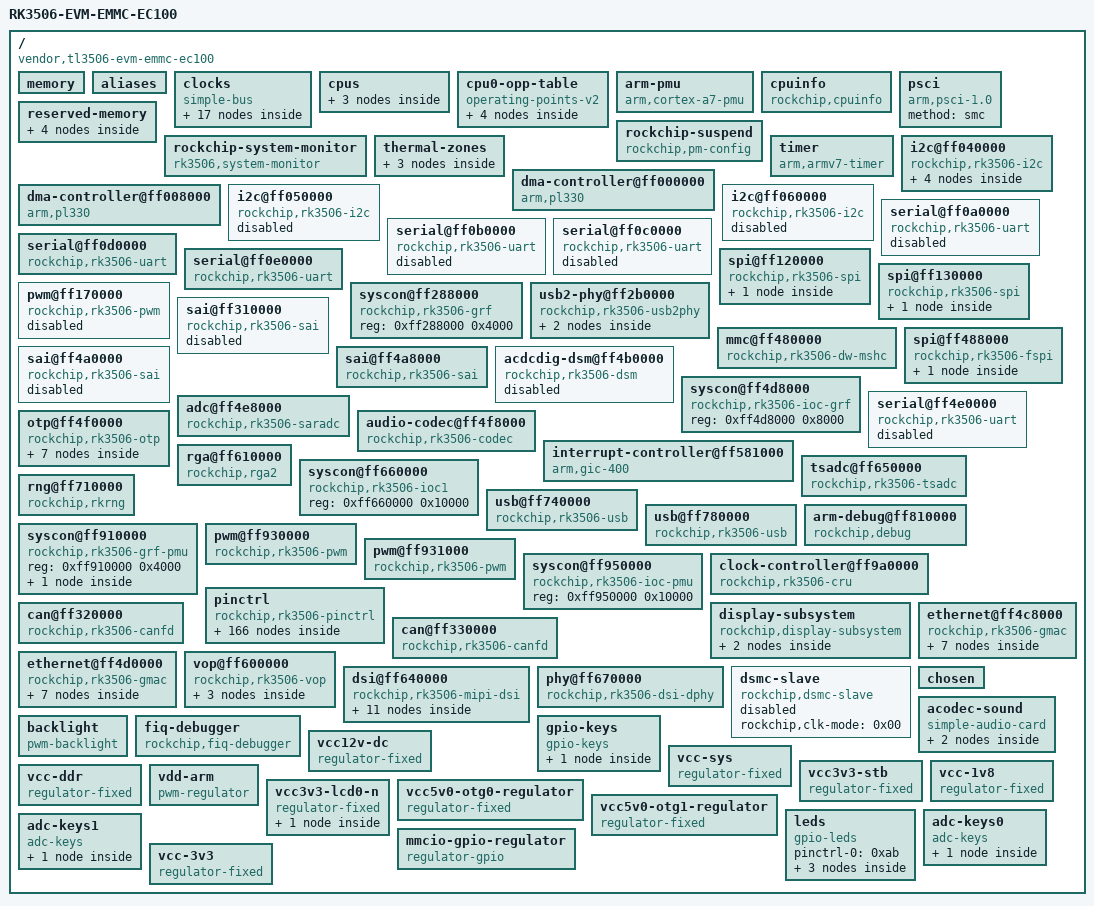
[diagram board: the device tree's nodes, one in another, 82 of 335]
/dts-v1/;

/memreserve/	0x0000000000063000 0x000000000000b000;
/ {
	serial-number = "e6a45d5007608a23";
	#address-cells = <0x01>;
	#size-cells = <0x01>;
	compatible = "vendor,tl3506-evm-emmc-ec100\0rockchip,rk3506";
	interrupt-parent = <0x01>;
	model = "RK3506-EVM-EMMC-EC100";

	memory {
		reg = <0x00 0x20000000 0x00 0x00 0x00 0x00 0x00 0x00 0x00 0x00 0x00 0x00 0x00 0x00 0x00 0x00 0x00 0x00 0x00 0x00 0x00 0x00 0x00 0x00>;
		device_type = "memory";
	};

	aliases {
		gpio0 = "/pinctrl/gpio@ff940000";
		gpio1 = "/pinctrl/gpio@ff870000";
		gpio2 = "/pinctrl/gpio@ff1c0000";
		gpio3 = "/pinctrl/gpio@ff1d0000";
		gpio4 = "/pinctrl/gpio@ff1e0000";
		i2c0 = "/i2c@ff040000";
		i2c1 = "/i2c@ff050000";
		i2c2 = "/i2c@ff060000";
		serial0 = "/serial@ff0a0000";
		serial1 = "/serial@ff0b0000";
		serial2 = "/serial@ff0c0000";
		serial3 = "/serial@ff0d0000";
		serial4 = "/serial@ff0e0000";
		serial5 = "/serial@ff4e0000";
		spi0 = "/spi@ff120000";
		spi1 = "/spi@ff130000";
		spi2 = "/spi@ff488000";
		spi3 = "/flexbus@ff880000/fspi";
		spi4 = "/flexbus@ff880000/spi";
		ethernet0 = "/ethernet@ff4c8000";
		ethernet1 = "/ethernet@ff4d0000";
		gpio5 = "/i2c@ff040000/gpio@20";
	};

	clocks {
		compatible = "simple-bus";
		#address-cells = <0x01>;
		#size-cells = <0x01>;
		ranges;

		clk-rc {
			compatible = "fixed-clock";
			#clock-cells = <0x00>;
			clock-frequency = <0x61a80>;
			clock-output-names = "clk_rc";
		};

		xin24m {
			compatible = "fixed-clock";
			#clock-cells = <0x00>;
			clock-frequency = <0x16e3600>;
			clock-output-names = "xin24m";
		};

		xin32k {
			compatible = "fixed-clock";
			#clock-cells = <0x00>;
			clock-frequency = <0x8000>;
			clock-output-names = "xin32k";
		};

		clk-spdifrx-to-asrc {
			compatible = "fixed-clock";
			#clock-cells = <0x00>;
			clock-frequency = <0x00>;
			clock-output-names = "clk_spdifrx_to_asrc";
		};

		mclkin-sai0 {
			compatible = "fixed-clock";
			#clock-cells = <0x00>;
			clock-frequency = <0x00>;
			clock-output-names = "sai0_mclk_in";
		};

		mclkin-sai1 {
			compatible = "fixed-clock";
			#clock-cells = <0x00>;
			clock-frequency = <0x00>;
			clock-output-names = "sai1_mclk_in";
		};

		mclkin-sai2 {
			compatible = "fixed-clock";
			#clock-cells = <0x00>;
			clock-frequency = <0x00>;
			clock-output-names = "sai2_mclk_in";
		};

		mclkin-sai3 {
			compatible = "fixed-clock";
			#clock-cells = <0x00>;
			clock-frequency = <0x00>;
			clock-output-names = "sai3_mclk_in";
		};

		mclkout-sai0@ff910004 {
			compatible = "rockchip,clk-out";
			reg = <0xff910004 0x04>;
			clocks = <0x02 0x9e>;
			#clock-cells = <0x00>;
			clock-output-names = "mclk_sai0_to_io";
			rockchip,bit-shift = <0x08>;
		};

		mclkout-sai1@ff910004 {
			compatible = "rockchip,clk-out";
			reg = <0xff910004 0x04>;
			clocks = <0x02 0xa1>;
			#clock-cells = <0x00>;
			clock-output-names = "mclk_sai1_to_io";
			rockchip,bit-shift = <0x09>;
			phandle = <0x10>;
		};

		mclkout-sai2@ff288004 {
			compatible = "rockchip,clk-out";
			reg = <0xff288004 0x04>;
			clocks = <0x02 0xc1>;
			#clock-cells = <0x00>;
			clock-output-names = "mclk_sai2_to_io";
			rockchip,bit-shift = <0x02>;
		};

		mclkout-sai3@ff288004 {
			compatible = "rockchip,clk-out";
			reg = <0xff288004 0x04>;
			clocks = <0x02 0xc5>;
			#clock-cells = <0x00>;
			clock-output-names = "mclk_sai3_to_io";
			rockchip,bit-shift = <0x03>;
		};

		pvtpll-core@ff840000 {
			compatible = "rockchip,rk3506-core-pvtpll\0syscon";
			reg = <0xff840000 0x100>;
			#clock-cells = <0x00>;
			clock-output-names = "clk_core_pvtpll";
			assigned-clocks = <0x03>;
			assigned-clock-rates = <0x47868c00>;
			phandle = <0x03>;
		};

		sai0-fs {
			compatible = "fixed-clock";
			#clock-cells = <0x00>;
			clock-frequency = <0x00>;
			clock-output-names = "sai0_fs";
		};

		sai1-fs {
			compatible = "fixed-clock";
			#clock-cells = <0x00>;
			clock-frequency = <0x00>;
			clock-output-names = "sai1_fs";
		};

		sai2-fs {
			compatible = "fixed-clock";
			#clock-cells = <0x00>;
			clock-frequency = <0x00>;
			clock-output-names = "sai2_fs";
		};

		sai3-fs {
			compatible = "fixed-clock";
			#clock-cells = <0x00>;
			clock-frequency = <0x00>;
			clock-output-names = "sai3_fs";
		};
	};

	cpus {
		#address-cells = <0x01>;
		#size-cells = <0x00>;

		cpu@f00 {
			device_type = "cpu";
			compatible = "arm,cortex-a7";
			reg = <0xf00>;
			enable-method = "psci";
			clocks = <0x02 0x0f>;
			operating-points-v2 = <0x04>;
			cpu-supply = <0x05>;
			phandle = <0x07>;
		};

		cpu@f01 {
			device_type = "cpu";
			compatible = "arm,cortex-a7";
			reg = <0xf01>;
			enable-method = "psci";
			clocks = <0x02 0x0f>;
			operating-points-v2 = <0x04>;
			phandle = <0x08>;
		};

		cpu@f02 {
			device_type = "cpu";
			compatible = "arm,cortex-a7";
			reg = <0xf02>;
			enable-method = "psci";
			clocks = <0x02 0x0f>;
			operating-points-v2 = <0x04>;
			phandle = <0x09>;
		};
	};

	cpu0-opp-table {
		compatible = "operating-points-v2";
		opp-shared;
		nvmem-cells = <0x06>;
		nvmem-cell-names = "leakage";
		rockchip,pvtm-voltage-sel = <0x00 0x630 0x00 0x631 0x653 0x01 0x654 0x676 0x02 0x677 0x699 0x03 0x69a 0x6bc 0x04 0x6bd 0x6df 0x05 0x6e0 0x702 0x06 0x703 0x270f 0x07>;
		rockchip,pvtm-pvtpll;
		rockchip,pvtm-offset = <0x18>;
		rockchip,pvtm-sample-time = <0x1f4>;
		rockchip,pvtm-freq = <0x188940>;
		rockchip,pvtm-volt = <0xf4240>;
		rockchip,pvtm-ref-temp = <0x28>;
		rockchip,pvtm-temp-prop = <0x00 0x00>;
		rockchip,pvtm-thermal-zone = "soc-thermal";
		rockchip,grf = <0x03>;
		rockchip,temp-hysteresis = <0x1388>;
		rockchip,low-temp = <0x2710>;
		rockchip,low-temp-min-volt = <0xdbba0>;
		phandle = <0x04>;

		opp-600000000 {
			opp-hz = <0x00 0x23c34600>;
			opp-microvolt = <0xcf850 0xcf850 0xf4240>;
			clock-latency-ns = <0x9c40>;
			opp-suspend;
			status = "okay";
		};

		opp-800000000 {
			opp-hz = <0x00 0x2faf0800>;
			opp-microvolt = <0xcf850 0xcf850 0xf4240>;
			clock-latency-ns = <0x9c40>;
			status = "okay";
		};

		opp-1008000000 {
			opp-hz = <0x00 0x3c14dc00>;
			opp-microvolt = <0xcf850 0xcf850 0xf4240>;
			opp-microvolt-L0 = <0xd59f8 0xd59f8 0xf4240>;
			clock-latency-ns = <0x9c40>;
			status = "okay";
		};

		opp-1200000000 {
			opp-hz = <0x00 0x47868c00>;
			opp-microvolt = <0xcf850 0xcf850 0xf4240>;
			opp-microvolt-L0 = <0xd59f8 0xd59f8 0xf4240>;
			clock-latency-ns = <0x9c40>;
			status = "okay";
		};
	};

	arm-pmu {
		compatible = "arm,cortex-a7-pmu";
		interrupts = <0x00 0x79 0x04 0x00 0x7a 0x04 0x00 0x7b 0x04>;
		interrupt-affinity = <0x07 0x08 0x09>;
	};

	cpuinfo {
		compatible = "rockchip,cpuinfo";
		nvmem-cells = <0x0a 0x0b 0x0c>;
		nvmem-cell-names = "id\0cpu-version\0cpu-code";
	};

	psci {
		compatible = "arm,psci-1.0";
		method = "smc";
	};

	reserved-memory {
		#address-cells = <0x01>;
		#size-cells = <0x01>;
		ranges;

		trust@0 {
			reg = <0x00 0x62000>;
		};

		linux,cma {
			compatible = "shared-dma-pool";
			reusable;
			size = <0x1600000>;
			linux,cma-default;
		};

		drm-logo@0 {
			compatible = "rockchip,drm-logo";
			reg = <0x1d900000 0xb8000>;
			phandle = <0x74>;
		};

		ramoops@83000 {
			compatible = "ramoops";
			reg = <0x83000 0x2d000>;
			boot-log-size = <0xd000>;
			boot-log-count = <0x01>;
			console-size = <0x20000>;
			pmsg-size = <0x00>;
			ftrace-size = <0x00>;
			record-size = <0x00>;
		};
	};

	rockchip-suspend {
		compatible = "rockchip,pm-config";
		status = "okay";
		rockchip,sleep-mode-config = <0x2b4>;
		rockchip,wakeup-config = <0x08>;
		rockchip,apios-suspend = <0xc2c0>;
		rockchip,sleep-io-config = <0xff950208 0xc000800 0xff950200 0xc00080 0xff950204 0x30002>;
	};

	rockchip-system-monitor {
		compatible = "rk3506,system-monitor";
		rockchip,thermal-zone = "soc-thermal";
		rockchip,temp-ddr-ref-mode = <0xffff63c0 0x01 0x124f8 0x04>;
	};

	thermal-zones {

		soc-thermal {
			polling-delay-passive = <0x14>;
			polling-delay = <0x3e8>;
			thermal-sensors = <0x0d 0x00>;

			trips {

				soc-crit {
					temperature = <0x1c138>;
					hysteresis = <0x7d0>;
					type = "critical";
				};
			};
		};
	};

	timer {
		compatible = "arm,armv7-timer";
		interrupts = <0x01 0x0d 0x704 0x01 0x0e 0x704 0x01 0x0b 0x704 0x01 0x0a 0x704>;
		clock-frequency = <0x16e3600>;
	};

	dma-controller@ff000000 {
		compatible = "arm,pl330\0arm,primecell";
		reg = <0xff000000 0x4000>;
		interrupts = <0x00 0x74 0x04 0x00 0x75 0x04>;
		clocks = <0x02 0x48>;
		clock-names = "apb_pclk";
		#dma-cells = <0x05>;
		arm,pl330-periph-burst;
		phandle = <0x15>;
	};

	dma-controller@ff008000 {
		compatible = "arm,pl330\0arm,primecell";
		reg = <0xff008000 0x4000>;
		interrupts = <0x00 0x76 0x04 0x00 0x77 0x04>;
		clocks = <0x02 0x49>;
		clock-names = "apb_pclk";
		#dma-cells = <0x05>;
		arm,pl330-periph-burst;
		phandle = <0x1b>;
	};

	i2c@ff040000 {
		compatible = "rockchip,rk3506-i2c\0rockchip,rk3399-i2c";
		reg = <0xff040000 0x1000>;
		interrupts = <0x00 0x28 0x04>;
		#address-cells = <0x01>;
		#size-cells = <0x00>;
		clocks = <0x02 0x7c 0x02 0x7b>;
		clock-names = "i2c\0pclk";
		status = "okay";
		pinctrl-names = "default";
		pinctrl-0 = <0x0e 0x0f>;

		es8388@11 {
			status = "disabled";
			#sound-dai-cells = <0x00>;
			compatible = "everest,es8388\0everest,es8323";
			reg = <0x11>;
			clocks = <0x10>;
			clock-names = "mclk";
			assigned-clocks = <0x10>;
			assigned-clock-rates = <0xbb8000>;
			pinctrl-names = "default";
			pinctrl-0 = <0x11>;
			phandle = <0xa3>;
		};

		gpio@20 {
			status = "okay";
			compatible = "nxp,pca9555";
			reg = <0x20>;
			gpio-controller;
			#gpio-cells = <0x02>;
			gpio-group-num = <0xc8>;
			phandle = <0x12>;
		};

		ds1307@68 {
			compatible = "dallas,ds1307";
			reg = <0x68>;
		};

		lt8912b@48 {
			compatible = "lontium,lt8912b-hdmi";
			reg = <0x48>;
			reset-gpios = <0x12 0x02 0x01>;
			status = "okay";
		};
	};

	i2c@ff050000 {
		compatible = "rockchip,rk3506-i2c\0rockchip,rk3399-i2c";
		reg = <0xff050000 0x1000>;
		interrupts = <0x00 0x29 0x04>;
		#address-cells = <0x01>;
		#size-cells = <0x00>;
		clocks = <0x02 0x7e 0x02 0x7d>;
		clock-names = "i2c\0pclk";
		status = "disabled";
	};

	i2c@ff060000 {
		compatible = "rockchip,rk3506-i2c\0rockchip,rk3399-i2c";
		reg = <0xff060000 0x1000>;
		interrupts = <0x00 0x2a 0x04>;
		#address-cells = <0x01>;
		#size-cells = <0x00>;
		clocks = <0x02 0x80 0x02 0x7f>;
		clock-names = "i2c\0pclk";
		status = "disabled";
		clock-frequency = <0x61a80>;
		pinctrl-names = "default";
		pinctrl-0 = <0x13 0x14>;
	};

	serial@ff0a0000 {
		compatible = "rockchip,rk3506-uart\0snps,dw-apb-uart";
		reg = <0xff0a0000 0x100>;
		interrupts = <0x00 0x22 0x04>;
		reg-shift = <0x02>;
		reg-io-width = <0x04>;
		dmas = <0x15 0x04 0xff2880a8 0x3000100 0x00 0x00 0x15 0x05 0xff2880a8 0xc000400 0x00 0x00>;
		clocks = <0x02 0x76 0x02 0x71>;
		clock-names = "baudclk\0apb_pclk";
		pinctrl-names = "default";
		pinctrl-0 = <0x16>;
		status = "disabled";
	};

	serial@ff0b0000 {
		compatible = "rockchip,rk3506-uart\0snps,dw-apb-uart";
		reg = <0xff0b0000 0x100>;
		interrupts = <0x00 0x23 0x04>;
		reg-shift = <0x02>;
		reg-io-width = <0x04>;
		dmas = <0x15 0x06 0xff2880a8 0x30001000 0x00 0x00 0x15 0x07 0xff2880a8 0xc0004000 0x00 0x00>;
		clocks = <0x02 0x77 0x02 0x72>;
		clock-names = "baudclk\0apb_pclk";
		status = "disabled";
		pinctrl-names = "default";
		pinctrl-0 = <0x17 0x18>;
		dma-names = "tx\0rx";
	};

	serial@ff0c0000 {
		compatible = "rockchip,rk3506-uart\0snps,dw-apb-uart";
		reg = <0xff0c0000 0x100>;
		interrupts = <0x00 0x24 0x04>;
		reg-shift = <0x02>;
		reg-io-width = <0x04>;
		dmas = <0x15 0x08 0xff2880ac 0x30001 0x00 0x00 0x15 0x09 0xff2880ac 0xc0004 0x00 0x00>;
		clocks = <0x02 0x78 0x02 0x73>;
		clock-names = "baudclk\0apb_pclk";
		status = "disabled";
	};

	serial@ff0d0000 {
		compatible = "rockchip,rk3506-uart\0snps,dw-apb-uart";
		reg = <0xff0d0000 0x100>;
		interrupts = <0x00 0x25 0x04>;
		reg-shift = <0x02>;
		reg-io-width = <0x04>;
		dmas = <0x15 0x0a 0xff2880ac 0x300010 0x00 0x00 0x15 0x0b 0xff2880ac 0xc00040 0x00 0x00>;
		clocks = <0x02 0x79 0x02 0x74>;
		clock-names = "baudclk\0apb_pclk";
		status = "okay";
		pinctrl-names = "default";
		pinctrl-0 = <0x19 0x1a>;
	};

	serial@ff0e0000 {
		compatible = "rockchip,rk3506-uart\0snps,dw-apb-uart";
		reg = <0xff0e0000 0x100>;
		interrupts = <0x00 0x26 0x04>;
		reg-shift = <0x02>;
		reg-io-width = <0x04>;
		dmas = <0x1b 0x0c 0x00 0x00 0x00 0x00 0x1b 0x0d 0x00 0x00 0x00 0x00>;
		clocks = <0x02 0x7a 0x02 0x75>;
		clock-names = "baudclk\0apb_pclk";
		status = "okay";
		pinctrl-names = "default";
		pinctrl-0 = <0x1c 0x1d>;
	};

	spi@ff120000 {
		compatible = "rockchip,rk3506-spi\0rockchip,rk3066-spi";
		reg = <0xff120000 0x1000>;
		interrupts = <0x00 0x2b 0x04>;
		#address-cells = <0x01>;
		#size-cells = <0x00>;
		clocks = <0x02 0x88 0x02 0x87>;
		clock-names = "spiclk\0apb_pclk";
		dmas = <0x15 0x00 0xff2880a8 0x30001 0x00 0x00 0x15 0x01 0xff2880a8 0xc0004 0x00 0x00>;
		dma-names = "tx\0rx";
		num-cs = <0x01>;
		pinctrl-names = "default\0high_speed";
		pinctrl-0 = <0x1e 0x1f 0x20 0x21>;
		status = "okay";
		rockchip,pm-disable = <0x01>;
		rockchip,keep-clk-on = <0x01>;
		rockchip,rt;

		mm6108@0 {
			compatible = "morse,mm610x-spi";
			reg = <0x00>;
			spi-max-frequency = <0x2faf080>;
			spi-irq-gpios = <0x22 0x0d 0x00>;
			reset-gpios = <0x23 0x0b 0x00>;
			status = "okay";
		};
	};

	spi@ff130000 {
		compatible = "rockchip,rk3506-spi\0rockchip,rk3066-spi";
		reg = <0xff130000 0x1000>;
		interrupts = <0x00 0x2c 0x04>;
		#address-cells = <0x01>;
		#size-cells = <0x00>;
		clocks = <0x02 0x8a 0x02 0x89>;
		clock-names = "spiclk\0apb_pclk";
		dmas = <0x15 0x02 0xff2880a8 0x300010 0x00 0x00 0x15 0x03 0xff2880a8 0xc00040 0x00 0x00>;
		dma-names = "tx\0rx";
		num-cs = <0x02>;
		pinctrl-names = "default";
		pinctrl-0 = <0x24 0x25 0x26 0x27>;
		status = "okay";

		mmc-slot@0 {
			compatible = "mmc-spi-slot";
			reg = <0x00>;
			spi-max-frequency = <0x1312d00>;
			voltage-ranges = <0xce4 0xce4>;
			broken-cd;
			no-1-8-v;
			vmmc-supply = <0x28>;
			vqmmc-supply = <0x28>;
		};
	};

	pwm@ff170000 {
		compatible = "rockchip,rk3506-pwm\0rockchip,rk3576-pwm";
		reg = <0xff170000 0x200>;
		interrupts = <0x00 0x1a 0x04>;
		clocks = <0x02 0x82 0x02 0x81>;
		clock-names = "pwm\0pclk";
		#pwm-cells = <0x03>;
		status = "disabled";
		pinctrl-names = "active";
		pinctrl-0 = <0x29>;
		phandle = <0x9e>;
	};

	syscon@ff288000 {
		compatible = "rockchip,rk3506-grf\0syscon\0simple-mfd";
		reg = <0xff288000 0x4000>;
		phandle = <0x2b>;
	};

	usb2-phy@ff2b0000 {
		compatible = "rockchip,rk3506-usb2phy";
		reg = <0xff2b0000 0x8000>;
		clocks = <0x02 0x2a 0x02 0x65>;
		clock-names = "phyclk\0apb_pclk";
		#clock-cells = <0x00>;
		rockchip,usbgrf = <0x2b>;
		status = "okay";

		otg-port {
			#phy-cells = <0x00>;
			interrupts = <0x00 0x4b 0x04 0x00 0x4c 0x04 0x00 0x4d 0x04>;
			interrupt-names = "otg-bvalid\0otg-id\0linestate";
			status = "okay";
			vbus-supply = <0x2c>;
			phandle = <0x5b>;
		};

		host-port {
			#phy-cells = <0x00>;
			interrupts = <0x00 0x50 0x04 0x00 0x51 0x04 0x00 0x52 0x04>;
			interrupt-names = "otg-bvalid\0otg-id\0linestate";
			status = "okay";
			phy-supply = <0x2d>;
			phandle = <0x5c>;
		};
	};

	sai@ff310000 {
		compatible = "rockchip,rk3506-sai\0rockchip,sai-v1";
		reg = <0xff310000 0x1000>;
		interrupts = <0x00 0x33 0x04>;
		clocks = <0x02 0x9f 0x02 0xa0>;
		clock-names = "mclk\0hclk";
		dmas = <0x1b 0x03 0xff2880a4 0x4000000 0x00 0x00 0x1b 0x02 0xff2880a4 0x2000000 0x00 0x00>;
		dma-names = "tx\0rx";
		resets = <0x02 0xe2 0x02 0xe3>;
		reset-names = "m\0h";
		#sound-dai-cells = <0x00>;
		sound-name-prefix = "SAI1";
		pinctrl-names = "default\0sleep";
		pinctrl-0 = <0x35 0x36 0x37 0x38>;
		status = "disabled";
		pinctrl-1 = <0x39 0x3a 0x3b 0x3c>;
		phandle = <0xa2>;
	};

	mmc@ff480000 {
		compatible = "rockchip,rk3506-dw-mshc\0rockchip,rk3288-dw-mshc";
		reg = <0xff480000 0x4000>;
		interrupts = <0x00 0x56 0x04>;
		max-frequency = <0x8f0d180>;
		bus-width = <0x04>;
		clocks = <0x02 0xb4 0x02 0xb3>;
		clock-names = "biu\0ciu";
		fifo-depth = <0x100>;
		resets = <0x02 0x117>;
		reset-names = "reset";
		status = "okay";
		cap-sd-highspeed;
		no-sd;
		pinctrl-names = "default";
		pinctrl-0 = <0x45 0x46 0x47>;
		non-removable;
		no-sdio;
		cap-mmc-highspeed;
		vqmmc-supply = <0x48>;
		vmmc-supply = <0x28>;
		mmc-hs200-1_8v;
	};

	spi@ff488000 {
		compatible = "rockchip,rk3506-fspi\0rockchip,fspi";
		reg = <0xff488000 0x4000>;
		interrupts = <0x00 0x55 0x04>;
		clocks = <0x02 0xb6 0x02 0xb5>;
		clock-names = "clk_sfc\0hclk_sfc";
		rockchip,grf = <0x49>;
		rockchip,max-dll = <0x17f>;
		#address-cells = <0x01>;
		#size-cells = <0x00>;
		status = "okay";

		flash@0 {
			compatible = "jedec,spi-nor";
			reg = <0x00>;
			spi-max-frequency = <0x5f5e100>;
			spi-rx-bus-width = <0x04>;
			spi-tx-bus-width = <0x04>;
		};
	};

	sai@ff4a0000 {
		compatible = "rockchip,rk3506-sai\0rockchip,sai-v1";
		reg = <0xff4a0000 0x1000>;
		interrupts = <0x00 0x35 0x04>;
		clocks = <0x02 0xc4 0x02 0xc3>;
		clock-names = "mclk\0hclk";
		dmas = <0x1b 0x06 0x00 0x00 0x00 0x00 0x1b 0x07 0x00 0x00 0x00 0x00>;
		dma-names = "tx\0rx";
		resets = <0x02 0x127 0x02 0x126>;
		reset-names = "m\0h";
		#sound-dai-cells = <0x00>;
		sound-name-prefix = "SAI3";
		pinctrl-names = "default";
		pinctrl-0 = <0x4e 0x4f 0x50 0x51>;
		status = "disabled";
		phandle = <0xa0>;
	};

	sai@ff4a8000 {
		compatible = "rockchip,rk3506-sai\0rockchip,sai-v1";
		reg = <0xff4a8000 0x1000>;
		interrupts = <0x00 0x36 0x04>;
		clocks = <0x02 0xc8 0x02 0xc7>;
		clock-names = "mclk\0hclk";
		dmas = <0x1b 0x08 0x00 0x00 0x00 0x00>;
		dma-names = "rx";
		resets = <0x02 0x12b 0x02 0x12a>;
		reset-names = "m\0h";
		#sound-dai-cells = <0x00>;
		sound-name-prefix = "SAI4";
		status = "okay";
		phandle = <0x9c>;
	};

	acdcdig-dsm@ff4b0000 {
		compatible = "rockchip,rk3506-dsm";
		reg = <0xff4b0000 0x1000>;
		clocks = <0x02 0xca 0x02 0xc9>;
		clock-names = "dac\0pclk";
		resets = <0x02 0x12d>;
		reset-names = "reset";
		rockchip,grf = <0x2b>;
		rockchip,dsm-audm-en = <0x01>;
		pinctrl-names = "audm0-iodown\0audm0-pins\0audm1-iodown\0audm1-pins\0audm0m1-iodown\0audm0m1-pins";
		pinctrl-0 = <0x52>;
		pinctrl-1 = <0x53>;
		pinctrl-2 = <0x54>;
		pinctrl-3 = <0x55>;
		pinctrl-4 = <0x52 0x54>;
		pinctrl-5 = <0x53 0x55>;
		#sound-dai-cells = <0x00>;
		status = "disabled";
		phandle = <0xa1>;
	};

	syscon@ff4d8000 {
		compatible = "rockchip,rk3506-ioc-grf\0syscon";
		reg = <0xff4d8000 0x8000>;
		phandle = <0x66>;
	};

	serial@ff4e0000 {
		compatible = "rockchip,rk3506-uart\0snps,dw-apb-uart";
		reg = <0xff4e0000 0x100>;
		interrupts = <0x00 0x27 0x04>;
		reg-shift = <0x02>;
		reg-io-width = <0x04>;
		dmas = <0x1b 0x0e 0x00 0x00 0x00 0x00 0x1b 0x0f 0x00 0x00 0x00 0x00>;
		clocks = <0x02 0xd4 0x02 0xd3>;
		clock-names = "baudclk\0apb_pclk";
		pinctrl-names = "default";
		pinctrl-0 = <0x56 0x57>;
		status = "disabled";
	};

	adc@ff4e8000 {
		compatible = "rockchip,rk3506-saradc\0rockchip,rk3562-saradc";
		reg = <0xff4e8000 0x8000>;
		interrupts = <0x00 0x39 0x04>;
		#io-channel-cells = <0x01>;
		clocks = <0x02 0xcf 0x02 0xce>;
		clock-names = "saradc\0apb_pclk";
		resets = <0x02 0x130>;
		reset-names = "saradc-apb";
		status = "okay";
		vref-supply = <0x58>;
		phandle = <0xac>;
	};

	otp@ff4f0000 {
		compatible = "rockchip,rk3506-otp";
		reg = <0xff4f0000 0x4000>;
		#address-cells = <0x01>;
		#size-cells = <0x01>;
		clocks = <0x02 0xd2 0x02 0xd1 0x02 0xd0>;
		clock-names = "usr\0sbpi\0apb";
		resets = <0x02 0x135 0x02 0x134 0x02 0x133>;
		reset-names = "usr\0sbpi\0apb";

		cpu-code@2 {
			reg = <0x02 0x02>;
			phandle = <0x0c>;
		};

		cpu-version@5 {
			reg = <0x05 0x01>;
			bits = <0x03 0x03>;
			phandle = <0x0b>;
		};

		id@a {
			reg = <0x0a 0x10>;
			phandle = <0x0a>;
		};

		cpu-leakage@1e {
			reg = <0x1e 0x01>;
			phandle = <0x06>;
		};

		log-leakage@1f {
			reg = <0x1f 0x01>;
		};

		cpu-tsadc-trim-l@20 {
			reg = <0x20 0x01>;
			phandle = <0x59>;
		};

		cpu-tsadc-trim-h@21 {
			reg = <0x21 0x01>;
			bits = <0x00 0x02>;
			phandle = <0x5a>;
		};
	};

	audio-codec@ff4f8000 {
		compatible = "rockchip,rk3506-codec";
		reg = <0xff4f8000 0x1000>;
		#sound-dai-cells = <0x00>;
		clocks = <0x02 0xcb 0x02 0xcc>;
		clock-names = "pclk\0mclk";
		resets = <0x02 0x12f>;
		reset-names = "rst";
		status = "okay";
		phandle = <0x9d>;
	};

	interrupt-controller@ff581000 {
		compatible = "arm,gic-400";
		reg = <0xff581000 0x1000 0xff582000 0x2000 0xff584000 0x2000 0xff586000 0x2000>;
		interrupts = <0x01 0x09 0x04>;
		#interrupt-cells = <0x03>;
		interrupt-controller;
		#address-cells = <0x00>;
		phandle = <0x01>;
	};

	rga@ff610000 {
		compatible = "rockchip,rga2";
		reg = <0xff610000 0x1000>;
		interrupts = <0x00 0x3d 0x04>;
		interrupt-names = "rga2_irq";
		clocks = <0x02 0xde 0x02 0xdd 0x02 0xdf>;
		clock-names = "aclk_rga\0hclk_rga\0clk_rga";
		status = "okay";
	};

	tsadc@ff650000 {
		compatible = "rockchip,rk3506-tsadc";
		reg = <0xff650000 0x400>;
		interrupts = <0x00 0x3a 0x04>;
		clocks = <0x02 0xe6 0x02 0xe5 0x02 0xe7>;
		clock-names = "tsadc\0apb_pclk\0tsen";
		assigned-clocks = <0x02 0xe6 0x02 0xe7>;
		assigned-clock-rates = <0xf4240 0xb71b00>;
		resets = <0x02 0x15f 0x02 0x15e>;
		reset-names = "tsadc\0tsadc-apb";
		#thermal-sensor-cells = <0x01>;
		rockchip,grf = <0x2b>;
		rockchip,hw-tshut-temp = <0x1d4c0>;
		rockchip,hw-tshut-mode = <0x00>;
		rockchip,hw-tshut-polarity = <0x00>;
		nvmem-cells = <0x59 0x5a>;
		nvmem-cell-names = "trim_l\0trim_h";
		status = "okay";
		phandle = <0x0d>;
	};

	syscon@ff660000 {
		compatible = "rockchip,rk3506-ioc1\0syscon";
		reg = <0xff660000 0x10000>;
		phandle = <0x67>;
	};

	rng@ff710000 {
		compatible = "rockchip,rkrng";
		reg = <0xff710000 0x200>;
		interrupts = <0x00 0x72 0x04>;
		clocks = <0x02 0xfc>;
		clock-names = "hclk_trng";
		resets = <0x02 0x60>;
		reset-names = "reset";
		status = "okay";
	};

	usb@ff740000 {
		compatible = "rockchip,rk3506-usb\0rockchip,rk3066-usb\0snps,dwc2";
		reg = <0xff740000 0x40000>;
		interrupts = <0x00 0x4a 0x04>;
		clocks = <0x02 0x5f 0x02 0x60 0x02 0x61>;
		clock-names = "otg\0pmu\0adp";
		dr_mode = "otg";
		phys = <0x5b>;
		phy-names = "usb2-phy";
		g-np-tx-fifo-size = <0x10>;
		g-rx-fifo-size = <0x118>;
		g-tx-fifo-size = <0x100 0x80 0x80 0x40 0x20 0x10>;
		status = "okay";
	};

	usb@ff780000 {
		compatible = "rockchip,rk3506-usb\0rockchip,rk3066-usb\0snps,dwc2";
		reg = <0xff780000 0x40000>;
		interrupts = <0x00 0x4f 0x04>;
		clocks = <0x02 0x62 0x02 0x63 0x02 0x64>;
		clock-names = "otg\0pmu\0adp";
		dr_mode = "host";
		phys = <0x5c>;
		phy-names = "usb2-phy";
		g-np-tx-fifo-size = <0x10>;
		g-rx-fifo-size = <0x118>;
		g-tx-fifo-size = <0x100 0x80 0x80 0x40 0x20 0x10>;
		status = "okay";
	};

	arm-debug@ff810000 {
		compatible = "rockchip,debug";
		reg = <0xff810000 0x1000 0xff812000 0x1000 0xff814000 0x1000>;
	};

	syscon@ff910000 {
		compatible = "rockchip,rk3506-grf-pmu\0syscon\0simple-mfd";
		reg = <0xff910000 0x4000>;
		phandle = <0x49>;

		reboot-mode {
			compatible = "syscon-reboot-mode";
			offset = <0x200>;
			mode-bootloader = <0x5242c301>;
			mode-charge = <0x5242c30b>;
			mode-fastboot = <0x5242c309>;
			mode-loader = <0x5242c301>;
			mode-normal = <0x5242c300>;
			mode-recovery = <0x5242c303>;
			mode-ums = <0x5242c30c>;
			mode-panic = <0x5242c307>;
			mode-watchdog = <0x5242c308>;
		};
	};

	pwm@ff930000 {
		compatible = "rockchip,rk3506-pwm\0rockchip,rk3576-pwm";
		reg = <0xff930000 0x200>;
		interrupts = <0x00 0x16 0x04>;
		clocks = <0x02 0x10b 0x02 0x10a 0x02 0x10c>;
		clock-names = "pwm\0pclk\0osc";
		#pwm-cells = <0x03>;
		status = "okay";
		pinctrl-names = "active";
		pinctrl-0 = <0x63>;
		phandle = <0xa9>;
	};

	pwm@ff931000 {
		compatible = "rockchip,rk3506-pwm\0rockchip,rk3576-pwm";
		reg = <0xff931000 0x200>;
		interrupts = <0x00 0x17 0x04>;
		clocks = <0x02 0x10b 0x02 0x10a 0x02 0x10c>;
		clock-names = "pwm\0pclk\0osc";
		#pwm-cells = <0x03>;
		status = "okay";
		pinctrl-names = "active";
		pinctrl-0 = <0x64>;
	};

	syscon@ff950000 {
		compatible = "rockchip,rk3506-ioc-pmu\0syscon";
		reg = <0xff950000 0x10000>;
		phandle = <0x68>;
	};

	clock-controller@ff9a0000 {
		compatible = "rockchip,rk3506-cru";
		reg = <0xff9a0000 0x20000>;
		rockchip,grf = <0x2b>;
		#clock-cells = <0x01>;
		#reset-cells = <0x01>;
		phandle = <0x02>;
	};

	pinctrl {
		compatible = "rockchip,rk3506-pinctrl";
		rockchip,grf = <0x66>;
		rockchip,ioc1 = <0x67>;
		rockchip,pmu = <0x68>;
		rockchip,rmio = <0x49>;
		#address-cells = <0x01>;
		#size-cells = <0x01>;
		ranges;
		pinctrl-names = "default";
		pinctrl-0 = <0x69>;
		phandle = <0x6a>;

		gpio@ff940000 {
			compatible = "rockchip,gpio-bank";
			reg = <0xff940000 0x200>;
			interrupts = <0x00 0x00 0x04>;
			clocks = <0x02 0x103 0x02 0x104>;
			gpio-controller;
			#gpio-cells = <0x02>;
			gpio-ranges = <0x6a 0x00 0x00 0x20>;
			interrupt-controller;
			#interrupt-cells = <0x02>;
			phandle = <0x22>;
		};

		gpio@ff870000 {
			compatible = "rockchip,gpio-bank";
			reg = <0xff870000 0x200>;
			interrupts = <0x00 0x04 0x04>;
			clocks = <0x02 0x35 0x02 0x36>;
			gpio-controller;
			#gpio-cells = <0x02>;
			gpio-ranges = <0x6a 0x00 0x20 0x20>;
			interrupt-controller;
			#interrupt-cells = <0x02>;
			phandle = <0x7d>;
		};

		gpio@ff1c0000 {
			compatible = "rockchip,gpio-bank";
			reg = <0xff1c0000 0x200>;
			interrupts = <0x00 0x08 0x04>;
			clocks = <0x02 0x8b 0x02 0x8c>;
			gpio-controller;
			#gpio-cells = <0x02>;
			gpio-ranges = <0x6a 0x00 0x40 0x20>;
			interrupt-controller;
			#interrupt-cells = <0x02>;
		};

		gpio@ff1d0000 {
			compatible = "rockchip,gpio-bank";
			reg = <0xff1d0000 0x200>;
			interrupts = <0x00 0x0c 0x04>;
			clocks = <0x02 0x8d 0x02 0x8e>;
			gpio-controller;
			#gpio-cells = <0x02>;
			gpio-ranges = <0x6a 0x00 0x60 0x20>;
			interrupt-controller;
			#interrupt-cells = <0x02>;
		};

		gpio@ff1e0000 {
			compatible = "rockchip,gpio-bank";
			reg = <0xff1e0000 0x200>;
			interrupts = <0x00 0x10 0x04>;
			clocks = <0x02 0x8f 0x02 0x90>;
			gpio-controller;
			#gpio-cells = <0x02>;
			gpio-ranges = <0x6a 0x00 0x80 0x20>;
			interrupt-controller;
			#interrupt-cells = <0x02>;
			phandle = <0x23>;
		};

		pcfg-pull-up {
			bias-pull-up;
			phandle = <0x6d>;
		};

		pcfg-pull-down {
			bias-pull-down;
			phandle = <0x6c>;
		};

		pcfg-pull-none {
			bias-disable;
			phandle = <0x6b>;
		};

		pcfg-pull-none-drv-level-0 {
			bias-disable;
			drive-strength = <0x00>;
			phandle = <0x70>;
		};

		pcfg-pull-none-drv-level-1 {
			bias-disable;
			drive-strength = <0x01>;
			phandle = <0x72>;
		};

		pcfg-pull-none-drv-level-3 {
			bias-disable;
			drive-strength = <0x03>;
			phandle = <0x6e>;
		};

		pcfg-pull-none-drv-level-4 {
			bias-disable;
			drive-strength = <0x04>;
			phandle = <0x6f>;
		};

		pcfg-input-enable-pull-down {
			input-enable;
			bias-pull-down;
			phandle = <0x71>;
		};

		dsm_aud {

			dsm-audm0-pins {
				rockchip,pins = <0x01 0x18 0x04 0x6b 0x01 0x19 0x04 0x6b 0x01 0x11 0x04 0x6b 0x01 0x12 0x04 0x6b>;
				phandle = <0x53>;
			};

			dsm-audm1-pins {
				rockchip,pins = <0x02 0x0e 0x02 0x6b 0x02 0x0f 0x02 0x6b 0x02 0x0c 0x02 0x6b 0x02 0x0d 0x02 0x6b>;
				phandle = <0x55>;
			};

			dsm-audm0-iodown-pins {
				rockchip,pins = <0x01 0x18 0x00 0x6c 0x01 0x19 0x00 0x6c 0x01 0x11 0x00 0x6c 0x01 0x12 0x00 0x6c>;
				phandle = <0x52>;
			};

			dsm-audm1-iodown-pins {
				rockchip,pins = <0x02 0x0e 0x00 0x6c 0x02 0x0f 0x00 0x6c 0x02 0x0c 0x00 0x6c 0x02 0x0d 0x00 0x6c>;
				phandle = <0x54>;
			};
		};

		dsmc {

			dsmc-int-pins {
				rockchip,pins = <0x01 0x01 0x04 0x6c 0x01 0x10 0x04 0x6c>;
				phandle = <0x99>;
			};

			dsmc-clk-pins {
				rockchip,pins = <0x01 0x01 0x02 0x6d 0x01 0x10 0x02 0x6d>;
				phandle = <0x97>;
			};

			dsmc-csn-pins {
				rockchip,pins = <0x01 0x0e 0x02 0x6d 0x01 0x09 0x02 0x6d 0x01 0x1a 0x02 0x6d 0x01 0x1b 0x02 0x6d>;
				phandle = <0x98>;
			};

			dsmc-bus16-pins {
				rockchip,pins = <0x01 0x00 0x02 0x6c 0x01 0x03 0x02 0x6c 0x01 0x04 0x02 0x6c 0x01 0x05 0x02 0x6c 0x01 0x06 0x02 0x6c 0x01 0x07 0x02 0x6c 0x01 0x08 0x02 0x6c 0x01 0x0c 0x02 0x6c 0x01 0x0d 0x02 0x6c 0x01 0x11 0x02 0x6c 0x01 0x12 0x02 0x6c 0x01 0x13 0x02 0x6c 0x01 0x14 0x02 0x6c 0x01 0x15 0x02 0x6c 0x01 0x16 0x02 0x6c 0x01 0x17 0x02 0x6c 0x01 0x18 0x02 0x6c 0x01 0x02 0x02 0x6c 0x01 0x19 0x02 0x6c 0x01 0x0a 0x02 0x6c 0x01 0x0b 0x02 0x6c 0x01 0x0f 0x02 0x6c>;
				phandle = <0x96>;
			};

			dsmc-csn-pull-pins {
				rockchip,pins = <0x01 0x0e 0x00 0x6d 0x01 0x09 0x00 0x6d 0x01 0x1a 0x00 0x6d 0x01 0x1b 0x00 0x6d>;
				phandle = <0x95>;
			};
		};

		dsmc_slv {

			dsmc-slv-csn0-pins {
				rockchip,pins = <0x01 0x1a 0x08 0x6d>;
				phandle = <0x94>;
			};

			dsmc-slv-bus8-pins {
				rockchip,pins = <0x01 0x10 0x08 0x6c 0x01 0x12 0x08 0x6c 0x01 0x13 0x08 0x6c 0x01 0x14 0x08 0x6c 0x01 0x15 0x08 0x6c 0x01 0x16 0x08 0x6c 0x01 0x17 0x08 0x6c 0x01 0x18 0x08 0x6c 0x01 0x19 0x08 0x6c 0x01 0x11 0x08 0x6c 0x01 0x01 0x08 0x6c 0x01 0x1b 0x08 0x6c>;
				phandle = <0x93>;
			};

			dsmc-slv-csn0-pull-pins {
				rockchip,pins = <0x01 0x1a 0x00 0x6d>;
				phandle = <0x92>;
			};
		};

		eth_rmii0 {

			eth-rmii0-miim-pins {
				rockchip,pins = <0x02 0x0e 0x01 0x6b 0x02 0x0f 0x01 0x6b>;
				phandle = <0x7e>;
			};

			eth-rmii0-rx-bus2-pins {
				rockchip,pins = <0x02 0x08 0x01 0x6b 0x02 0x09 0x01 0x6b 0x02 0x10 0x01 0x6b>;
				phandle = <0x80>;
			};

			eth-rmii0-tx-bus2-pins {
				rockchip,pins = <0x02 0x0b 0x01 0x6b 0x02 0x0c 0x01 0x6b 0x02 0x0d 0x01 0x6b>;
				phandle = <0x7f>;
			};

			eth-rmii0-clk-pins {
				rockchip,pins = <0x02 0x0a 0x01 0x6b>;
				phandle = <0x81>;
			};
		};

		eth_rmii1 {

			eth-rmii1-miim-pins {
				rockchip,pins = <0x03 0x0c 0x02 0x6b 0x03 0x0d 0x02 0x6b>;
				phandle = <0x86>;
			};

			eth-rmii1-rx-bus2-pins {
				rockchip,pins = <0x03 0x06 0x02 0x6b 0x03 0x07 0x02 0x6b 0x03 0x0e 0x02 0x6b>;
				phandle = <0x88>;
			};

			eth-rmii1-tx-bus2-pins {
				rockchip,pins = <0x03 0x09 0x02 0x6b 0x03 0x0a 0x02 0x6b 0x03 0x0b 0x02 0x6b>;
				phandle = <0x87>;
			};

			eth-rmii1-clk-pins {
				rockchip,pins = <0x03 0x08 0x02 0x6b>;
				phandle = <0x89>;
			};
		};

		flexbus0 {

			flexbus0m1-pins {
				rockchip,pins = <0x01 0x0a 0x05 0x6b>;
				phandle = <0x5d>;
			};

			flexbus0-clk-pins {
				rockchip,pins = <0x01 0x11 0x03 0x6b>;
				phandle = <0x5e>;
			};

			flexbus0-d0-pins {
				rockchip,pins = <0x01 0x1b 0x03 0x6b>;
				phandle = <0x5f>;
			};

			flexbus0-d1-pins {
				rockchip,pins = <0x01 0x1a 0x03 0x6b>;
				phandle = <0x60>;
			};

			flexbus0-d2-pins {
				rockchip,pins = <0x01 0x19 0x03 0x6b>;
				phandle = <0x61>;
			};

			flexbus0-d3-pins {
				rockchip,pins = <0x01 0x18 0x03 0x6b>;
				phandle = <0x62>;
			};
		};

		sai0 {

			sai0-lrck-pins {
				rockchip,pins = <0x00 0x00 0x01 0x6b>;
				phandle = <0x2e>;
			};

			sai0-sclk-pins {
				rockchip,pins = <0x00 0x01 0x01 0x6b>;
				phandle = <0x2f>;
			};

			sai0-sdi0-pins {
				rockchip,pins = <0x00 0x04 0x01 0x6b>;
				phandle = <0x30>;
			};

			sai0-sdi1-pins {
				rockchip,pins = <0x00 0x05 0x01 0x6b>;
				phandle = <0x31>;
			};

			sai0-sdi2-pins {
				rockchip,pins = <0x00 0x06 0x01 0x6b>;
				phandle = <0x32>;
			};

			sai0-sdi3-pins {
				rockchip,pins = <0x00 0x07 0x01 0x6b>;
				phandle = <0x33>;
			};

			sai0-sdo-pins {
				rockchip,pins = <0x00 0x03 0x01 0x6b>;
				phandle = <0x34>;
			};
		};

		sai2 {

			sai2m0-lrck-pins {
				rockchip,pins = <0x03 0x09 0x01 0x6b>;
				phandle = <0x4a>;
			};

			sai2m0-sclk-pins {
				rockchip,pins = <0x03 0x07 0x01 0x6b>;
				phandle = <0x4b>;
			};

			sai2m0-sdi-pins {
				rockchip,pins = <0x03 0x06 0x01 0x6b>;
				phandle = <0x4c>;
			};

			sai2m0-sdo-pins {
				rockchip,pins = <0x03 0x08 0x01 0x6b>;
				phandle = <0x4d>;
			};
		};

		sai3 {

			sai3-lrck-pins {
				rockchip,pins = <0x02 0x0d 0x03 0x6b>;
				phandle = <0x4e>;
			};

			sai3-sclk-pins {
				rockchip,pins = <0x02 0x0c 0x03 0x6b>;
				phandle = <0x4f>;
			};

			sai3-sdi-pins {
				rockchip,pins = <0x02 0x0e 0x03 0x6b>;
				phandle = <0x50>;
			};

			sai3-sdo-pins {
				rockchip,pins = <0x02 0x0f 0x03 0x6b>;
				phandle = <0x51>;
			};
		};

		sdmmc {

			sdmmc-bus4-pins {
				rockchip,pins = <0x03 0x02 0x01 0x6d 0x03 0x03 0x01 0x6d 0x03 0x04 0x01 0x6d 0x03 0x05 0x01 0x6d>;
				phandle = <0x47>;
			};

			sdmmc-clk-pins {
				rockchip,pins = <0x03 0x00 0x01 0x6b>;
				phandle = <0x45>;
			};

			sdmmc-cmd-pins {
				rockchip,pins = <0x03 0x01 0x01 0x6d>;
				phandle = <0x46>;
			};

			vccio4_gpio {
				rockchip,pins = <0x00 0x18 0x00 0x6b>;
				phandle = <0xad>;
			};

			sd-det {
				rockchip,pins = <0x00 0x08 0x00 0x6d>;
			};
		};

		uart0 {

			uart0-xfer-pins {
				rockchip,pins = <0x00 0x17 0x01 0x6d 0x00 0x16 0x01 0x6d>;
				phandle = <0x16>;
			};
		};

		uart5 {

			uart5m0-xfer-pins {
				rockchip,pins = <0x03 0x0b 0x01 0x6d 0x03 0x0c 0x01 0x6d>;
				phandle = <0x56>;
			};

			uart5m0-ctsn-pins {
				rockchip,pins = <0x03 0x0a 0x01 0x6b>;
				phandle = <0x57>;
			};
		};

		rm_io_idle {

			rm-io9-idle-pins {
				rockchip,pins = <0x00 0x09 0x00 0x71>;
				phandle = <0x39>;
			};

			rm-io10-idle-pins {
				rockchip,pins = <0x00 0x0a 0x00 0x71>;
				phandle = <0x3a>;
			};

			rm-io11-idle-pins {
				rockchip,pins = <0x00 0x0b 0x00 0x71>;
				phandle = <0x3b>;
			};

			rm-io12-idle-pins {
				rockchip,pins = <0x00 0x0c 0x00 0x71>;
				phandle = <0x3c>;
			};
		};

		rm_io0 {

			rm-io0-uart4-rx {
				rockchip,pins = <0x00 0x00 0x19 0x6d>;
				phandle = <0x1c>;
			};

			rm-io0-pdm-clk0 {
				rockchip,pins = <0x00 0x00 0x24 0x6b>;
				phandle = <0x3d>;
			};

			rm-io0-pdm-sdi0 {
				rockchip,pins = <0x00 0x00 0x25 0x6b>;
				phandle = <0x3f>;
			};

			rm-io0-pdm-sdi1 {
				rockchip,pins = <0x00 0x00 0x26 0x6b>;
				phandle = <0x40>;
			};

			rm-io0-pdm-sdi2 {
				rockchip,pins = <0x00 0x00 0x27 0x6b>;
				phandle = <0x41>;
			};

			rm-io0-pdm-sdi3 {
				rockchip,pins = <0x00 0x00 0x28 0x6b>;
				phandle = <0x42>;
			};

			rm-io0-spdif-tx {
				rockchip,pins = <0x00 0x00 0x5f 0x6b>;
				phandle = <0x43>;
			};

			rm-io0-spdif-rx {
				rockchip,pins = <0x00 0x00 0x60 0x6b>;
				phandle = <0x44>;
			};

			rm-io0-pdm-clk1 {
				rockchip,pins = <0x00 0x00 0x6d 0x6b>;
				phandle = <0x3e>;
			};
		};

		rm_io2 {

			rm-io2-uart3-tx {
				rockchip,pins = <0x00 0x02 0x14 0x6b>;
				phandle = <0x1a>;
			};
		};

		rm_io3 {

			rm-io3-uart3-rx {
				rockchip,pins = <0x00 0x03 0x15 0x6d>;
				phandle = <0x19>;
			};

			rm-io3-pwm0-ch2 {
				rockchip,pins = <0x00 0x03 0x2f 0x72>;
				phandle = <0x65>;
			};
		};

		rm_io4 {

			rm-io4-i2c2-scl {
				rockchip,pins = <0x00 0x04 0x22 0x6b>;
				phandle = <0x13>;
			};
		};

		rm_io5 {

			rm-io5-i2c2-sda {
				rockchip,pins = <0x00 0x05 0x23 0x6b>;
				phandle = <0x14>;
			};
		};

		rm_io6 {

			rm-io6-i2c0-sda {
				rockchip,pins = <0x00 0x06 0x1f 0x6b>;
				phandle = <0x0f>;
			};
		};

		rm_io7 {

			rm-io7-i2c0-scl {
				rockchip,pins = <0x00 0x07 0x1e 0x6b>;
				phandle = <0x0e>;
			};
		};

		rm_io8 {

			rm-io8-uart4-tx {
				rockchip,pins = <0x00 0x08 0x18 0x6b>;
				phandle = <0x1d>;
			};

			rm-io8-sai1-mclk {
				rockchip,pins = <0x00 0x08 0x4a 0x6b>;
				phandle = <0x11>;
			};
		};

		rm_io9 {

			rm-io9-sai1-sclk {
				rockchip,pins = <0x00 0x09 0x4b 0x6b>;
				phandle = <0x35>;
			};
		};

		rm_io10 {

			rm-io10-sai1-lrck {
				rockchip,pins = <0x00 0x0a 0x4c 0x6b>;
				phandle = <0x36>;
			};

			rm-io10-spi0-csn0 {
				rockchip,pins = <0x00 0x0a 0x55 0x6e>;
				phandle = <0x21>;
			};
		};

		rm_io11 {

			rm-io11-sai1-sdi {
				rockchip,pins = <0x00 0x0b 0x4d 0x6b>;
				phandle = <0x37>;
			};

			rm-io11-spi0-clk {
				rockchip,pins = <0x00 0x0b 0x52 0x6e>;
				phandle = <0x1e>;
			};
		};

		rm_io12 {

			rm-io12-sai1-sdo0 {
				rockchip,pins = <0x00 0x0c 0x4e 0x6b>;
				phandle = <0x38>;
			};

			rm-io12-spi0-mosi {
				rockchip,pins = <0x00 0x0c 0x53 0x6e>;
				phandle = <0x20>;
			};
		};

		rm_io14 {

			rm-io14-spi0-miso {
				rockchip,pins = <0x00 0x0e 0x54 0x6e>;
				phandle = <0x1f>;
			};
		};

		rm_io17 {

			rm-io17-can1-tx {
				rockchip,pins = <0x00 0x11 0x29 0x6b>;
				phandle = <0x78>;
			};
		};

		rm_io18 {

			rm-io18-uart1-tx {
				rockchip,pins = <0x00 0x12 0x10 0x6b>;
				phandle = <0x17>;
			};

			rm-io18-can1-rx {
				rockchip,pins = <0x00 0x12 0x2a 0x6b>;
				phandle = <0x79>;
			};
		};

		rm_io19 {

			rm-io19-uart1-rx {
				rockchip,pins = <0x00 0x13 0x11 0x6d>;
				phandle = <0x18>;
			};

			rm-io19-can0-tx {
				rockchip,pins = <0x00 0x13 0x2b 0x6b>;
				phandle = <0x76>;
			};
		};

		rm_io20 {

			rm-io20-can0-rx {
				rockchip,pins = <0x00 0x14 0x2c 0x6b>;
				phandle = <0x77>;
			};

			rm-io20-pwm0-ch1 {
				rockchip,pins = <0x00 0x14 0x2e 0x72>;
				phandle = <0x64>;
			};

			rm-io20-pwm1-ch0 {
				rockchip,pins = <0x00 0x14 0x31 0x72>;
				phandle = <0x29>;
			};
		};

		rm_io21 {

			rm-io21-pwm0-ch0 {
				rockchip,pins = <0x00 0x15 0x2d 0x72>;
				phandle = <0x63>;
			};
		};

		rm_io25 {

			rm-io25-spi1-mosi {
				rockchip,pins = <0x01 0x0a 0x58 0x6b>;
				phandle = <0x25>;
			};
		};

		rm_io26 {

			rm-io26-spi1-csn0 {
				rockchip,pins = <0x01 0x0b 0x5a 0x6b>;
				phandle = <0x24>;
			};
		};

		rm_io27 {

			rm-io27-spi1-clk {
				rockchip,pins = <0x01 0x12 0x57 0x6b>;
				phandle = <0x26>;
			};
		};

		rm_io28 {

			rm-io28-spi1-miso {
				rockchip,pins = <0x01 0x13 0x59 0x6b>;
				phandle = <0x27>;
			};
		};

		gpio-keys {

			key-wake-up {
				rockchip,pins = <0x00 0x11 0x00 0x6b>;
			};
		};

		sdio-pwrseq {

			wifi-enable-h {
				rockchip,pins = <0x00 0x0f 0x00 0x6b>;
			};
		};

		speaker {

			spk-ctrl {
				rockchip,pins = <0x01 0x16 0x00 0x6b>;
				phandle = <0xa4>;
			};
		};

		wireless-bluetooth {

			uart5-gpios {
				rockchip,pins = <0x03 0x0d 0x00 0x6b>;
			};
		};

		wireless-wlan {

			wifi-wake-host {
				rockchip,pins = <0x00 0x10 0x00 0x6d>;
			};
		};

		usb {

			vcc5v0-otg0-en {
				rockchip,pins = <0x01 0x18 0x00 0x6b>;
				phandle = <0xaa>;
			};

			vcc5v0-otg1-en {
				rockchip,pins = <0x01 0x18 0x00 0x6b>;
			};
		};

		leds {

			som-led {
				rockchip,pins = <0x00 0x05 0x00 0x6d>;
				phandle = <0x69>;
			};

			user-led {
				rockchip,pins = <0x04 0x0b 0x00 0x6b>;
				phandle = <0xab>;
			};
		};

		keys {

			user2-key {
				rockchip,pins = <0x04 0x0a 0x00 0x6d>;
				phandle = <0xa5>;
			};
		};

		run-led {
			rockchip,pins = <0x01 0x07 0x00 0x6b>;
		};

		led1 {
			rockchip,pins = <0x01 0x06 0x00 0x6b>;
		};

		led2 {
			rockchip,pins = <0x01 0x04 0x00 0x6b>;
		};

		user-reset {
			rockchip,pins = <0x01 0x05 0x00 0x6d>;
		};

		wdt {
			rockchip,pins = <0x00 0x09 0x00 0x6b>;
		};

		modem-reset-pin {
			rockchip,pins = <0x01 0x19 0x00 0x6b>;
		};

		modem-power-pin {
			rockchip,pins = <0x01 0x10 0x00 0x6b>;
		};

		spi0-int-pin {
			rockchip,pins = <0x00 0x0d 0x00 0x6b>;
		};
	};

	display-subsystem {
		compatible = "rockchip,display-subsystem";
		ports = <0x73>;
		status = "okay";
		logo-memory-region = <0x74>;

		route {

			route-dsi {
				overscan,bottom_margin = <0x64>;
				overscan,top_margin = <0x64>;
				overscan,right_margin = <0x64>;
				overscan,left_margin = <0x64>;
				video,aspect_ratio = <0x00>;
				video,flags = <0x06>;
				video,vrefresh = <0x3c>;
				video,crtc_vsync_end = <0x2da>;
				video,crtc_hsync_end = <0x596>;
				video,vdisplay = <0x2d0>;
				video,hdisplay = <0x500>;
				video,clock = <0x1220a>;
				logo,ymirror = <0x00>;
				logo,bpp = <0x10>;
				logo,height = <0x10e>;
				logo,width = <0x28e>;
				logo,offset = <0x61000>;
				status = "okay";
				logo,uboot = "logo.bmp";
				logo,kernel = "logo_kernel.bmp";
				logo,mode = "center";
				charge_logo,mode = "center";
				connect = <0x75>;
			};
		};
	};

	can@ff320000 {
		compatible = "rockchip,rk3506-canfd\0rockchip,rk3576-canfd";
		reg = <0xff320000 0x1000>;
		interrupts = <0x00 0x2d 0x04>;
		clocks = <0x02 0x92 0x02 0x91>;
		clock-names = "baudclk\0apb_pclk";
		resets = <0x02 0xd5 0x02 0xd4>;
		reset-names = "can\0can-apb";
		assigned-clocks = <0x02 0x92>;
		assigned-clock-rates = <0x11e1a300>;
		status = "okay";
		pinctrl-0 = <0x76 0x77>;
		pinctrl-names = "default";
	};

	can@ff330000 {
		compatible = "rockchip,rk3506-canfd\0rockchip,rk3576-canfd";
		reg = <0xff330000 0x1000>;
		interrupts = <0x00 0x2e 0x04>;
		clocks = <0x02 0x94 0x02 0x93>;
		clock-names = "baudclk\0apb_pclk";
		resets = <0x02 0xd7 0x02 0xd6>;
		reset-names = "can\0can-apb";
		assigned-clocks = <0x02 0x94>;
		assigned-clock-rates = <0x11e1a300>;
		status = "okay";
		pinctrl-names = "default";
		pinctrl-0 = <0x78 0x79>;
	};

	ethernet@ff4c8000 {
		local-mac-address = [ee 8a 55 bb 85 41];
		compatible = "rockchip,rk3506-gmac\0snps,dwmac-4.20a";
		reg = <0xff4c8000 0x2000>;
		interrupts = <0x00 0x42 0x04 0x00 0x45 0x04>;
		interrupt-names = "macirq\0eth_wake_irq";
		rockchip,grf = <0x2b>;
		clocks = <0x02 0xbd 0x02 0xd7 0x02 0xba 0x02 0xb8>;
		clock-names = "stmmaceth\0ptp_ref\0pclk_mac\0aclk_mac";
		resets = <0x02 0x11b>;
		reset-names = "stmmaceth";
		snps,mixed-burst;
		snps,tso;
		snps,axi-config = <0x7a>;
		snps,mtl-rx-config = <0x7b>;
		snps,mtl-tx-config = <0x7c>;
		phy-mode = "rmii";
		status = "okay";
		clock_in_out = "input";
		snps,reset-gpio = <0x7d 0x03 0x01>;
		snps,reset-active-low;
		snps,reset-delays-us = <0x4e20 0x4e20 0x4e20>;
		pinctrl-names = "default";
		pinctrl-0 = <0x7e 0x7f 0x80 0x81>;
		phy-handle = <0x82>;

		mdio {
			compatible = "snps,dwmac-mdio";
			#address-cells = <0x01>;
			#size-cells = <0x00>;

			phy@0 {
				compatible = "ethernet-phy-ieee802.3-c22";
				reg = <0x00>;
				phandle = <0x82>;
			};
		};

		stmmac-axi-config {
			snps,wr_osr_lmt = <0x04>;
			snps,rd_osr_lmt = <0x08>;
			snps,blen = <0x00 0x00 0x00 0x00 0x10 0x08 0x04>;
			phandle = <0x7a>;
		};

		rx-queues-config {
			snps,rx-queues-to-use = <0x01>;
			phandle = <0x7b>;

			queue0 {
				status = "okay";
			};
		};

		tx-queues-config {
			snps,tx-queues-to-use = <0x01>;
			phandle = <0x7c>;

			queue0 {
				status = "okay";
			};
		};
	};

	ethernet@ff4d0000 {
		local-mac-address = [f2 8a 55 bb 85 41];
		compatible = "rockchip,rk3506-gmac\0snps,dwmac-4.20a";
		reg = <0xff4d0000 0x2000>;
		interrupts = <0x00 0x46 0x04 0x00 0x49 0x04>;
		interrupt-names = "macirq\0eth_wake_irq";
		rockchip,grf = <0x2b>;
		clocks = <0x02 0xbe 0x02 0xd8 0x02 0xbb 0x02 0xb9>;
		clock-names = "stmmaceth\0ptp_ref\0pclk_mac\0aclk_mac";
		resets = <0x02 0x11c>;
		reset-names = "stmmaceth";
		snps,mixed-burst;
		snps,tso;
		snps,axi-config = <0x83>;
		snps,mtl-rx-config = <0x84>;
		snps,mtl-tx-config = <0x85>;
		phy-mode = "rmii";
		status = "okay";
		clock_in_out = "input";
		snps,reset-gpio = <0x7d 0x02 0x01>;
		snps,reset-active-low;
		snps,reset-delays-us = <0x4e20 0x4e20 0x4e20>;
		pinctrl-names = "default";
		pinctrl-0 = <0x86 0x87 0x88 0x89>;
		phy-handle = <0x8a>;

		mdio {
			compatible = "snps,dwmac-mdio";
			#address-cells = <0x01>;
			#size-cells = <0x00>;

			phy@0 {
				compatible = "ethernet-phy-ieee802.3-c22";
				reg = <0x00>;
				phandle = <0x8a>;
			};
		};

		stmmac-axi-config {
			snps,wr_osr_lmt = <0x04>;
			snps,rd_osr_lmt = <0x08>;
			snps,blen = <0x00 0x00 0x00 0x00 0x10 0x08 0x04>;
			phandle = <0x83>;
		};

		rx-queues-config {
			snps,rx-queues-to-use = <0x01>;
			phandle = <0x84>;

			queue0 {
				status = "okay";
			};
		};

		tx-queues-config {
			snps,tx-queues-to-use = <0x01>;
			phandle = <0x85>;

			queue0 {
				status = "okay";
			};
		};
	};

	vop@ff600000 {
		compatible = "rockchip,rk3506-vop";
		reg = <0xff600000 0x200 0xff600a00 0x400>;
		reg-names = "regs\0gamma_lut";
		rockchip,grf = <0x2b>;
		interrupts = <0x00 0x3b 0x04>;
		clocks = <0x02 0xe0 0x02 0xe2 0x02 0xe1>;
		clock-names = "aclk_vop\0dclk_vop\0hclk_vop";
		status = "okay";

		port {
			#address-cells = <0x01>;
			#size-cells = <0x00>;
			phandle = <0x73>;

			endpoint@0 {
				reg = <0x00>;
				remote-endpoint = <0x8b>;
				phandle = <0x2a>;
			};

			endpoint@1 {
				reg = <0x01>;
				remote-endpoint = <0x8c>;
				phandle = <0x75>;
			};
		};
	};

	dsi@ff640000 {
		compatible = "rockchip,rk3506-mipi-dsi";
		reg = <0xff640000 0x10000>;
		interrupts = <0x00 0x3c 0x04>;
		clocks = <0x02 0xe4>;
		clock-names = "pclk";
		resets = <0x02 0x15d>;
		reset-names = "apb";
		phys = <0x8d>;
		phy-names = "dphy";
		rockchip,grf = <0x2b>;
		#address-cells = <0x01>;
		#size-cells = <0x00>;
		status = "okay";
		rockchip,lane-rate = <0x352>;

		ports {
			#address-cells = <0x01>;
			#size-cells = <0x00>;

			port@0 {
				reg = <0x00>;
				#address-cells = <0x01>;
				#size-cells = <0x00>;

				endpoint@0 {
					reg = <0x00>;
					remote-endpoint = <0x75>;
					status = "okay";
					phandle = <0x8c>;
				};
			};

			port@1 {
				reg = <0x01>;

				endpoint {
					remote-endpoint = <0x8e>;
					phandle = <0x91>;
				};
			};
		};

		panel@0 {
			status = "okay";
			compatible = "simple-panel-dsi";
			reg = <0x00>;
			prepare-delay-ms = <0xc8>;
			reset-delay-ms = <0xc8>;
			init-delay-ms = <0xc8>;
			disable-delay-ms = <0xc8>;
			unprepare-delay-ms = <0xc8>;
			dsi,flags = <0x203>;
			dsi,format = <0x00>;
			dsi,lanes = <0x02>;
			power-supply = <0x8f>;

			display-timings {
				native-mode = <0x90>;

				timing0 {
					clock-frequency = <0x46cf710>;
					hactive = <0x500>;
					vactive = <0x2d0>;
					hfront-porch = <0x6e>;
					hsync-len = <0x28>;
					hback-porch = <0xdc>;
					vfront-porch = <0x05>;
					vsync-len = <0x05>;
					vback-porch = <0x14>;
					hsync-active = <0x00>;
					vsync-active = <0x01>;
					de-active = <0x00>;
					pixelclk-active = <0x00>;
					phandle = <0x90>;
				};
			};

			ports {
				#address-cells = <0x01>;
				#size-cells = <0x00>;

				port@0 {
					reg = <0x00>;

					endpoint {
						remote-endpoint = <0x91>;
						phandle = <0x8e>;
					};
				};
			};
		};
	};

	phy@ff670000 {
		compatible = "rockchip,rk3506-dsi-dphy";
		reg = <0xff670000 0x10000 0xff640000 0x10000>;
		reg-names = "phy\0host";
		clocks = <0x02 0x2b 0x02 0xe3 0x02 0xe4>;
		clock-names = "ref\0pclk\0pclk_host";
		#clock-cells = <0x00>;
		resets = <0x02 0x15c>;
		reset-names = "apb";
		#phy-cells = <0x00>;
		status = "okay";
		phandle = <0x8d>;
	};

	dsmc-slave {
		compatible = "rockchip,dsmc-slave";
		rockchip,clk-mode = <0x00>;
		status = "disabled";
		phandle = <0x9a>;
	};

	chosen {
		bootargs = "storagemedia=emmc androidboot.storagemedia=emmc androidboot.mode=normal  rootwait console=ttyFIQ0 root=/dev/mmcblk0p6 androidboot.fwver=ddr-v1.06-d27ac532c4,tee-v2.10,uboot-03/20/2026";
	};

	acodec-sound {
		compatible = "simple-audio-card";
		simple-audio-card,name = "rockchip,acodec";
		simple-audio-card,format = "i2s";
		simple-audio-card,mclk-fs = <0x400>;
		simple-audio-card,bitclock-master = <0x9b>;
		simple-audio-card,frame-master = <0x9b>;

		simple-audio-card,cpu {
			sound-dai = <0x9c>;
		};

		simple-audio-card,codec {
			sound-dai = <0x9d>;
			phandle = <0x9b>;
		};
	};

	backlight {
		compatible = "pwm-backlight";
		pwms = <0x9e 0x00 0x61a8 0x00>;
		brightness-levels = <0x00 0x14 0x14 0x15 0x15 0x16 0x16 0x17 0x17 0x18 0x18 0x19 0x19 0x1a 0x1a 0x1b 0x1b 0x1c 0x1c 0x1d 0x1d 0x1e 0x1e 0x1f 0x1f 0x20 0x20 0x21 0x21 0x22 0x22 0x23 0x23 0x24 0x24 0x25 0x25 0x26 0x26 0x27 0x28 0x29 0x2a 0x2b 0x2c 0x2d 0x2e 0x2f 0x30 0x31 0x32 0x33 0x34 0x35 0x36 0x37 0x38 0x39 0x3a 0x3b 0x3c 0x3d 0x3e 0x3f 0x40 0x41 0x42 0x43 0x44 0x45 0x46 0x47 0x48 0x49 0x4a 0x4b 0x4c 0x4d 0x4e 0x4f 0x50 0x51 0x52 0x53 0x54 0x55 0x56 0x57 0x58 0x59 0x5a 0x5b 0x5c 0x5d 0x5e 0x5f 0x60 0x61 0x62 0x63 0x64 0x65 0x66 0x67 0x68 0x69 0x6a 0x6b 0x6c 0x6d 0x6e 0x6f 0x70 0x71 0x72 0x73 0x74 0x75 0x76 0x77 0x78 0x79 0x7a 0x7b 0x7c 0x7d 0x7e 0x7f 0x80 0x81 0x82 0x83 0x84 0x85 0x86 0x87 0x88 0x89 0x8a 0x8b 0x8c 0x8d 0x8e 0x8f 0x90 0x91 0x92 0x93 0x94 0x95 0x96 0x97 0x98 0x99 0x9a 0x9b 0x9c 0x9d 0x9e 0x9f 0xa0 0xa1 0xa2 0xa3 0xa4 0xa5 0xa6 0xa7 0xa8 0xa9 0xaa 0xab 0xac 0xad 0xae 0xaf 0xb0 0xb1 0xb2 0xb3 0xb4 0xb5 0xb6 0xb7 0xb8 0xb9 0xba 0xbb 0xbc 0xbd 0xbe 0xbf 0xc0 0xc1 0xc2 0xc3 0xc4 0xc5 0xc6 0xc7 0xc8 0xc9 0xca 0xcb 0xcc 0xcd 0xce 0xcf 0xd0 0xd1 0xd2 0xd3 0xd4 0xd5 0xd6 0xd7 0xd8 0xd9 0xda 0xdb 0xdc 0xdd 0xde 0xdf 0xe0 0xe1 0xe2 0xe3 0xe4 0xe5 0xe6 0xe7 0xe8 0xe9 0xea 0xeb 0xec 0xed 0xee 0xef 0xf0 0xf1 0xf2 0xf3 0xf4 0xf5 0xf6 0xf7 0xf8 0xf9 0xfa 0xfb 0xfc 0xfd 0xfe 0xff>;
		default-brightness-level = <0xc8>;
		status = "okay";
	};

	fiq-debugger {
		compatible = "rockchip,fiq-debugger";
		rockchip,serial-id = <0x00>;
		rockchip,wake-irq = <0x00>;
		rockchip,irq-mode-enable = <0x01>;
		rockchip,baudrate = <0x1c200>;
		interrupts = <0x00 0x73 0x04>;
	};

	gpio-keys {
		compatible = "gpio-keys";
		pinctrl-names = "default";
		pinctrl-0 = <0xa5>;
		autorepeat;

		user2_key {
			label = "user2-key";
			linux,code = <0x94>;
			gpios = <0x23 0x0a 0x01>;
			debounce-interval = <0x00>;
		};
	};

	vcc12v-dc {
		compatible = "regulator-fixed";
		regulator-name = "vcc12v_dc";
		regulator-always-on;
		regulator-boot-on;
		regulator-min-microvolt = <0xb71b00>;
		regulator-max-microvolt = <0xb71b00>;
		phandle = <0xa6>;
	};

	vcc-sys {
		compatible = "regulator-fixed";
		regulator-name = "vcc_sys";
		regulator-always-on;
		regulator-boot-on;
		regulator-min-microvolt = <0x4c4b40>;
		regulator-max-microvolt = <0x4c4b40>;
		vin-supply = <0xa6>;
		phandle = <0xa7>;
	};

	vcc3v3-stb {
		compatible = "regulator-fixed";
		regulator-name = "vcc3v3_stb";
		regulator-always-on;
		regulator-boot-on;
		regulator-min-microvolt = <0x325aa0>;
		regulator-max-microvolt = <0x325aa0>;
		vin-supply = <0xa7>;
		phandle = <0xa8>;
	};

	vcc-1v8 {
		compatible = "regulator-fixed";
		regulator-name = "vcc_1v8";
		regulator-always-on;
		regulator-boot-on;
		regulator-min-microvolt = <0x1b7740>;
		regulator-max-microvolt = <0x1b7740>;
		vin-supply = <0xa8>;
		phandle = <0x58>;
	};

	vcc-ddr {
		compatible = "regulator-fixed";
		regulator-name = "vcc_ddr";
		regulator-always-on;
		regulator-boot-on;
		vin-supply = <0xa7>;
	};

	vdd-arm {
		compatible = "pwm-regulator";
		pwms = <0xa9 0x00 0x1388 0x01>;
		regulator-name = "vdd_arm";
		regulator-min-microvolt = <0xad570>;
		regulator-max-microvolt = <0x126ad8>;
		regulator-init-microvolt = <0xf6d38>;
		regulator-always-on;
		regulator-boot-on;
		regulator-settling-time-up-us = <0xfa>;
		pwm-supply = <0xa7>;
		phandle = <0x05>;
	};

	vcc3v3-lcd0-n {
		compatible = "regulator-fixed";
		regulator-name = "vcc3v3_lcd_n";
		regulator-boot-on;
		regulator-always-on;
		phandle = <0x8f>;

		regulator-state-mem {
			regulator-off-in-suspend;
		};
	};

	vcc5v0-otg0-regulator {
		compatible = "regulator-fixed";
		regulator-name = "vcc5v0_otg0";
		regulator-min-microvolt = <0x4c4b40>;
		regulator-max-microvolt = <0x4c4b40>;
		enable-active-high;
		gpio = <0x7d 0x18 0x00>;
		pinctrl-names = "default";
		pinctrl-0 = <0xaa>;
		phandle = <0x2c>;
	};

	vcc5v0-otg1-regulator {
		compatible = "regulator-fixed";
		regulator-name = "vcc5v0_otg1";
		regulator-boot-on;
		regulator-always-on;
		regulator-min-microvolt = <0x4c4b40>;
		regulator-max-microvolt = <0x4c4b40>;
		phandle = <0x2d>;
	};

	leds {
		status = "okay";
		compatible = "gpio-leds";
		pinctrl-names = "default";
		pinctrl-0 = <0xab>;

		som_led {
			label = "heartbeat";
			gpios = <0x22 0x05 0x00>;
			linux,default-trigger = "heartbeat";
			default-state = "off";
		};

		user_led {
			label = "user-led0";
			gpios = <0x23 0x0b 0x00>;
			linux,default-trigger = "default-on";
			default-state = "off";
		};

		pcie_power {
			label = "pcie_power";
			gpios = <0x7d 0x10 0x00>;
			default-state = "on";
			linux,default-trigger = "none";
		};
	};

	adc-keys0 {
		compatible = "adc-keys";
		io-channels = <0xac 0x00>;
		io-channel-names = "buttons";
		keyup-threshold-microvolt = <0x1b7740>;
		poll-interval = <0x64>;

		maskrom_key {
			label = "maskrom";
			linux,code = <0x94>;
			press-threshold-microvolt = <0x6d6>;
		};
	};

	adc-keys1 {
		compatible = "adc-keys";
		io-channels = <0xac 0x01>;
		io-channel-names = "buttons";
		keyup-threshold-microvolt = <0x1b7740>;
		poll-interval = <0x64>;

		user_key@1 {
			label = "user1-key";
			linux,code = <0x94>;
			press-threshold-microvolt = <0x6d6>;
		};
	};

	mmcio-gpio-regulator {
		compatible = "regulator-gpio";
		regulator-name = "mmcio-gpio-supply";
		regulator-min-microvolt = <0x1b7740>;
		regulator-max-microvolt = <0x325aa0>;
		pinctrl-names = "default";
		pinctrl-0 = <0xad>;
		gpios = <0x22 0x18 0x00>;
		gpios-states = <0x00>;
		states = <0x325aa0 0x01 0x1b7740 0x00>;
		startup-delay-us = <0x186a0>;
		phandle = <0x48>;
	};

	vcc-3v3 {
		compatible = "regulator-fixed";
		regulator-name = "vcc_3v3";
		regulator-always-on;
		regulator-boot-on;
		regulator-min-microvolt = <0x325aa0>;
		regulator-max-microvolt = <0x325aa0>;
		vin-supply = <0xa7>;
		phandle = <0x28>;
	};
};
